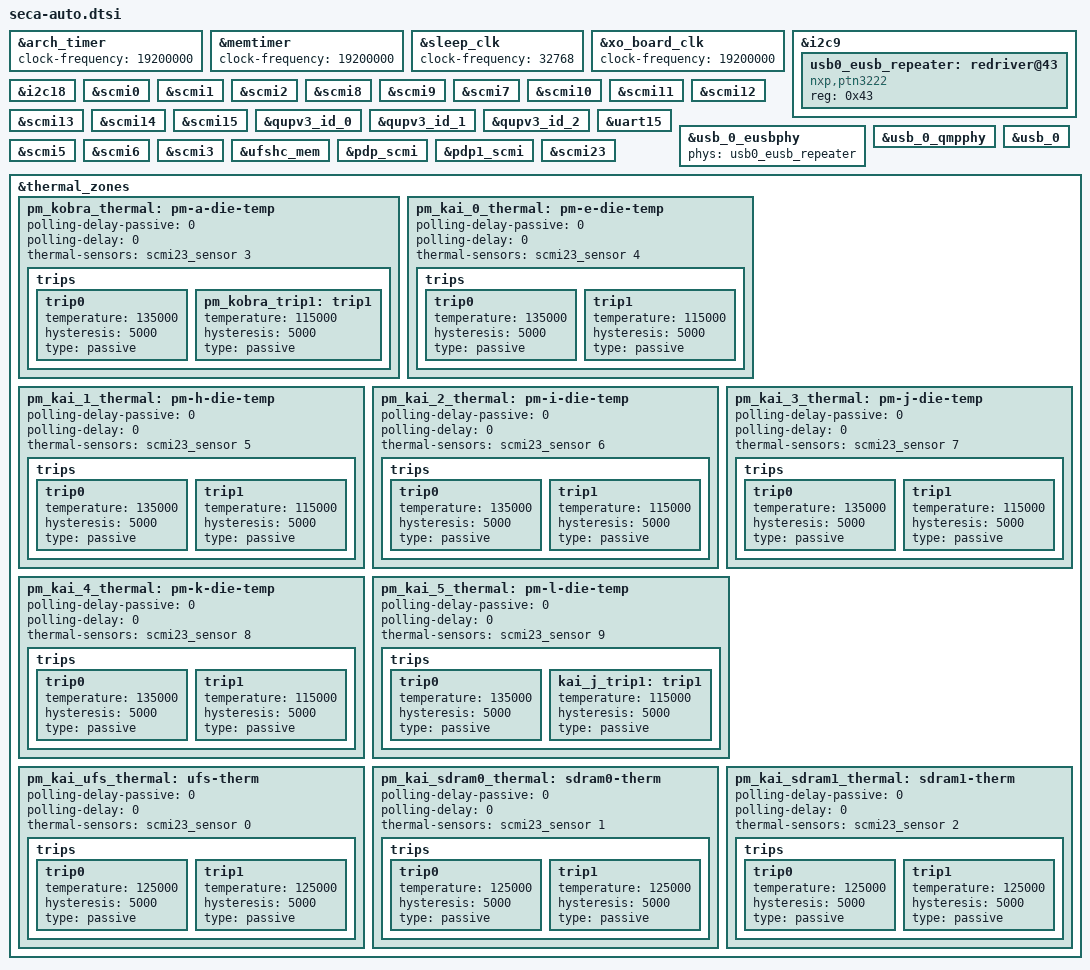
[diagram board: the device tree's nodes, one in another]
// SPDX-License-Identifier: BSD-3-Clause
/*
 * Copyright (c) Qualcomm Technologies, Inc. and/or its subsidiaries.
 */

#include "seca-usb.dtsi"
#include "seca-ethernet.dtsi"

&arch_timer {
	clock-frequency = <19200000>;
};

&memtimer {
	clock-frequency = <19200000>;
};

&sleep_clk {
	clock-frequency = <32768>;
};

&xo_board_clk {
	clock-frequency = <19200000>;
};

&i2c9 {
	status = "okay";

	#address-cells = <1>;
	#size-cells = <0>;

	usb0_eusb_repeater: redriver@43 {
		compatible = "nxp,ptn3222";
		reg = <0x43>;
		#phy-cells = <0>;
	};
};

&i2c18 {
	status = "okay";
};

&scmi0 {
	status = "okay";
};

&scmi1 {
	status = "okay";
};

&scmi2 {
	status = "okay";
};

&scmi8 {
	status = "okay";
};

&scmi9 {
	status = "okay";
};

&scmi7 {
	status = "okay";
};

&scmi10 {
	status = "okay";
};

&scmi11 {
	status = "okay";
};

&scmi12 {
	status = "okay";
};

&scmi13 {
	status = "okay";
};

&scmi14 {
	status = "okay";
};

&scmi15 {
	status = "okay";
};

&qupv3_id_0 {
	status = "okay";
};

&qupv3_id_1 {
	status = "okay";
};

&qupv3_id_2 {
	status = "okay";
};

&uart15 {
	status = "okay";
};

&usb_0_eusbphy {
	phys = <&usb0_eusb_repeater>;

	status = "okay";
};

&usb_0_qmpphy {
	status = "okay";
};

&usb_0 {
	status = "okay";
};

&scmi5 {
	status = "okay";
};

&scmi6 {
	status = "okay";
};

&scmi3 {
	status = "okay";
};

&ufshc_mem {
	status = "okay";
};

&pdp_scmi {
	status = "okay";
};

&pdp1_scmi {
	status = "okay";
};

&scmi23 {
	status = "okay";
};

&thermal_zones {
	pm_kobra_thermal: pm-a-die-temp {
		polling-delay-passive = <0>;
		polling-delay = <0>;
		thermal-sensors = <&scmi23_sensor 3>;

		trips {
			trip0 {
				temperature = <135000>;
				hysteresis = <5000>;
				type = "passive";
			};

			pm_kobra_trip1: trip1 {
				temperature = <115000>;
				hysteresis = <5000>;
				type = "passive";
			};
		};
	};

	pm_kai_0_thermal: pm-e-die-temp {
		polling-delay-passive = <0>;
		polling-delay = <0>;
		thermal-sensors = <&scmi23_sensor 4>;

		trips {
			trip0 {
				temperature = <135000>;
				hysteresis = <5000>;
				type = "passive";
			};

			trip1 {
				temperature = <115000>;
				hysteresis = <5000>;
				type = "passive";
			};
		};
	};

	pm_kai_1_thermal: pm-h-die-temp {
		polling-delay-passive = <0>;
		polling-delay = <0>;
		thermal-sensors = <&scmi23_sensor 5>;

		trips {
			trip0 {
				temperature = <135000>;
				hysteresis = <5000>;
				type = "passive";
			};

			trip1 {
				temperature = <115000>;
				hysteresis = <5000>;
				type = "passive";
			};
		};
	};

	pm_kai_2_thermal: pm-i-die-temp {
		polling-delay-passive = <0>;
		polling-delay = <0>;
		thermal-sensors = <&scmi23_sensor 6>;

		trips {
			trip0 {
				temperature = <135000>;
				hysteresis = <5000>;
				type = "passive";
			};

			trip1 {
				temperature = <115000>;
				hysteresis = <5000>;
				type = "passive";
			};
		};
	};

	pm_kai_3_thermal: pm-j-die-temp {
		polling-delay-passive = <0>;
		polling-delay = <0>;
		thermal-sensors = <&scmi23_sensor 7>;

		trips {
			trip0 {
				temperature = <135000>;
				hysteresis = <5000>;
				type = "passive";
			};

			trip1 {
				temperature = <115000>;
				hysteresis = <5000>;
				type = "passive";
			};
		};
	};

	pm_kai_4_thermal: pm-k-die-temp {
		polling-delay-passive = <0>;
		polling-delay = <0>;
		thermal-sensors = <&scmi23_sensor 8>;

		trips {
			trip0 {
				temperature = <135000>;
				hysteresis = <5000>;
				type = "passive";
			};

			trip1 {
				temperature = <115000>;
				hysteresis = <5000>;
				type = "passive";
			};
		};
	};

	pm_kai_5_thermal: pm-l-die-temp {
		polling-delay-passive = <0>;
		polling-delay = <0>;
		thermal-sensors = <&scmi23_sensor 9>;

		trips {
			trip0 {
				temperature = <135000>;
				hysteresis = <5000>;
				type = "passive";
			};

			kai_j_trip1: trip1 {
				temperature = <115000>;
				hysteresis = <5000>;
				type = "passive";
			};
		};
	};

	pm_kai_ufs_thermal: ufs-therm {
		polling-delay-passive = <0>;
		polling-delay = <0>;
		thermal-sensors = <&scmi23_sensor 0>;

		trips {
			trip0 {
				temperature = <125000>;
				hysteresis = <5000>;
				type = "passive";
			};

			trip1 {
				temperature = <125000>;
				hysteresis = <5000>;
				type = "passive";
			};
		};
	};

	pm_kai_sdram0_thermal: sdram0-therm {
		polling-delay-passive = <0>;
		polling-delay = <0>;
		thermal-sensors = <&scmi23_sensor 1>;

		trips {
			trip0 {
				temperature = <125000>;
				hysteresis = <5000>;
				type = "passive";
			};

			trip1 {
				temperature = <125000>;
				hysteresis = <5000>;
				type = "passive";
			};
		};
	};

	pm_kai_sdram1_thermal: sdram1-therm {
		polling-delay-passive = <0>;
		polling-delay = <0>;
		thermal-sensors = <&scmi23_sensor 2>;

		trips {
			trip0 {
				temperature = <125000>;
				hysteresis = <5000>;
				type = "passive";
			};

			trip1 {
				temperature = <125000>;
				hysteresis = <5000>;
				type = "passive";
			};
		};
	};
};
